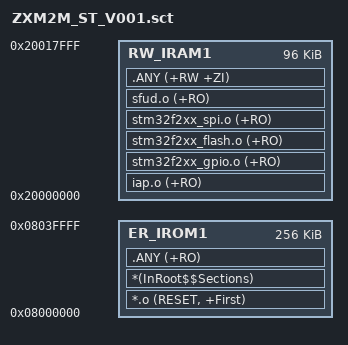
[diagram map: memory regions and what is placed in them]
; *************************************************************
; *** Scatter-Loading Description File generated by uVision ***
; *************************************************************

LR_IROM1 0x08000000 0x00040000  {    ; load region size_region
  ER_IROM1 0x08000000 0x00040000  {  ; load address = execution address
   *.o (RESET, +First)
   *(InRoot$$Sections)
   .ANY (+RO)
  }
  RW_IRAM1 0x20000000 0x00018000  {  ; RW data
    iap.o (+RO)
    stm32f2xx_gpio.o (+RO)
    stm32f2xx_flash.o (+RO)
    stm32f2xx_spi.o (+RO)
    sfud.o (+RO)
   .ANY (+RW +ZI)
  }
}

